VERSION "1.12"

NS_ :

BS_:

BU_: Master ODrive_Axis0

BO_ 0 Axis0_NMT: 0 Master

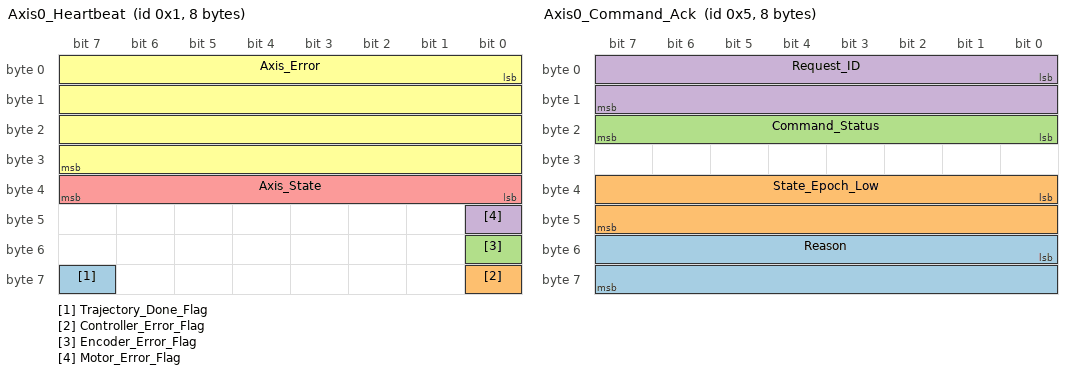
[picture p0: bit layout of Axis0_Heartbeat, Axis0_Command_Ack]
BO_ 1 Axis0_Heartbeat: 8 ODrive_Axis0
 SG_ Trajectory_Done_Flag : 63|1@1+ (1,0) [0|0] ""  Master
 SG_ Controller_Error_Flag : 56|1@1+ (1,0) [0|0] ""  Master
 SG_ Encoder_Error_Flag : 48|1@1+ (1,0) [0|0] ""  Master
 SG_ Motor_Error_Flag : 40|1@1+ (1,0) [0|0] ""  Master
 SG_ Axis_State : 32|8@1+ (1,0) [0|0] ""  Master
 SG_ Axis_Error : 0|32@1+ (1,0) [0|0] ""  Master

BO_ 2 Axis0_Estop: 0 Master

BO_ 3 Axis0_Get_Motor_Error: 8 ODrive_Axis0
 SG_ Motor_Error : 0|32@1+ (1,0) [0|0] ""  Master

BO_ 4 Axis0_Get_Encoder_Error: 8 ODrive_Axis0
 SG_ Encoder_Error : 0|32@1+ (1,0) [0|0] ""  Master

BO_ 5 Axis0_Command_Ack: 8 ODrive_Axis0
 SG_ Reason : 48|16@1+ (1,0) [0|0] ""  Master
 SG_ State_Epoch_Low : 32|16@1+ (1,0) [0|0] ""  Master
 SG_ Command_Status : 16|8@1+ (1,0) [0|0] ""  Master
 SG_ Request_ID : 0|16@1+ (1,0) [0|0] ""  Master

BO_ 6 Axis0_Set_Axis_Node_ID: 8 Master
 SG_ Axis_Node_ID : 0|32@1+ (1,0) [0|0] ""  ODrive_Axis0

BO_ 7 Axis0_Set_Axis_State: 8 Master
 SG_ Axis_Requested_State : 0|32@1+ (1,0) [0|0] ""  ODrive_Axis0

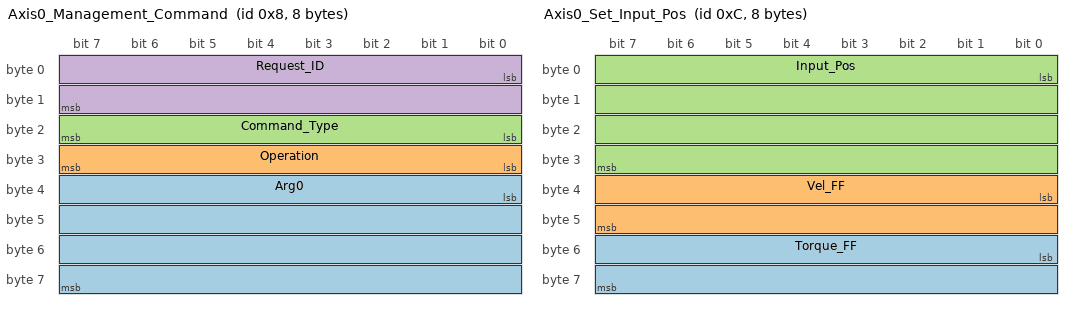
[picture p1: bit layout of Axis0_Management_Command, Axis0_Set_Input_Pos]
BO_ 8 Axis0_Management_Command: 8 Master
 SG_ Arg0 : 32|32@1+ (1,0) [0|0] ""  ODrive_Axis0
 SG_ Operation : 24|8@1+ (1,0) [0|0] ""  ODrive_Axis0
 SG_ Command_Type : 16|8@1+ (1,0) [0|0] ""  ODrive_Axis0
 SG_ Request_ID : 0|16@1+ (1,0) [0|0] ""  ODrive_Axis0

BO_ 9 Axis0_Get_Encoder_Estimates: 8 ODrive_Axis0
 SG_ Vel_Estimate : 32|32@1+ (1,0) [0|0] "rev/s"  Master
 SG_ Pos_Estimate : 0|32@1+ (1,0) [0|0] "rev"  Master

BO_ 10 Axis0_Get_Encoder_Count: 8 ODrive_Axis0
 SG_ Count_in_CPR : 32|32@1+ (1,0) [0|0] "counts"  Master
 SG_ Shadow_Count : 0|32@1+ (1,0) [0|0] "counts"  Master

BO_ 11 Axis0_Set_Controller_Mode: 8 Master
 SG_ Input_Mode : 32|32@1+ (1,0) [0|0] ""  ODrive_Axis0
 SG_ Control_Mode : 0|32@1+ (1,0) [0|0] ""  ODrive_Axis0

BO_ 12 Axis0_Set_Input_Pos: 8 Master
 SG_ Torque_FF : 48|16@1- (0.001,0) [0|0] "Nm"  ODrive_Axis0
 SG_ Vel_FF : 32|16@1- (0.001,0) [0|0] "rev/s"  ODrive_Axis0
 SG_ Input_Pos : 0|32@1+ (1,0) [0|0] "rev"  ODrive_Axis0

BO_ 13 Axis0_Set_Input_Vel: 8 Master
 SG_ Input_Torque_FF : 32|32@1+ (1,0) [0|0] "Nm"  ODrive_Axis0
 SG_ Input_Vel : 0|32@1+ (1,0) [0|0] "rev/s"  ODrive_Axis0

BO_ 14 Axis0_Set_Input_Torque: 8 Master
 SG_ Input_Torque : 0|32@1+ (1,0) [0|0] "Nm"  ODrive_Axis0

BO_ 15 Axis0_Set_Limits: 8 Master
 SG_ Current_Limit : 32|32@1+ (1,0) [0|0] "A"  ODrive_Axis0
 SG_ Velocity_Limit : 0|32@1+ (1,0) [0|0] "rev/s"  ODrive_Axis0

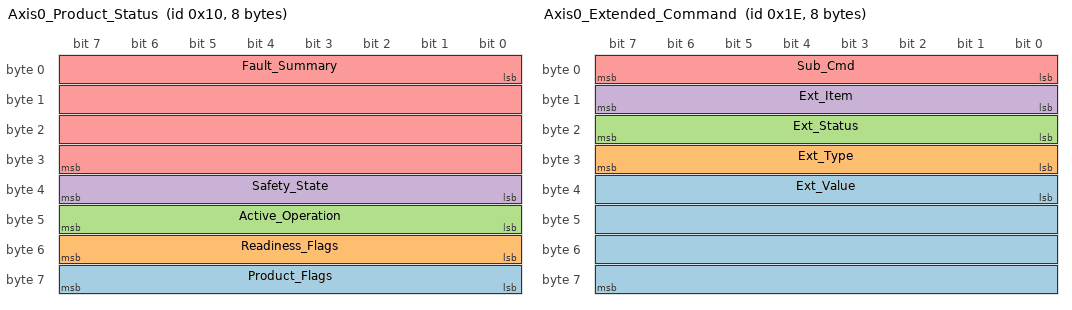
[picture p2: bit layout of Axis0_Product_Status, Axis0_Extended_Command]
BO_ 16 Axis0_Product_Status: 8 ODrive_Axis0
 SG_ Product_Flags : 56|8@1+ (1,0) [0|0] ""  Master
 SG_ Readiness_Flags : 48|8@1+ (1,0) [0|0] ""  Master
 SG_ Active_Operation : 40|8@1+ (1,0) [0|0] ""  Master
 SG_ Safety_State : 32|8@1+ (1,0) [0|0] ""  Master
 SG_ Fault_Summary : 0|32@1+ (1,0) [0|0] ""  Master

BO_ 17 Axis0_Set_Traj_Vel_Limit: 8 Master
 SG_ Traj_Vel_Limit : 0|32@1+ (1,0) [0|0] "rev/s"  ODrive_Axis0

BO_ 18 Axis0_Set_Traj_Accel_Limits: 8 Master
 SG_ Traj_Decel_Limit : 32|32@1+ (1,0) [0|0] "rev/s^2"  ODrive_Axis0
 SG_ Traj_Accel_Limit : 0|32@1+ (1,0) [0|0] "rev/s^2"  ODrive_Axis0

BO_ 19 Axis0_Set_Traj_Inertia: 8 Master
 SG_ Traj_Inertia : 0|32@1+ (1,0) [0|0] "Nm / (rev/s^2)"  ODrive_Axis0

BO_ 20 Axis0_Get_Iq: 8 ODrive_Axis0
 SG_ Iq_Measured : 32|32@1+ (1,0) [0|0] "A"  Master
 SG_ Iq_Setpoint : 0|32@1+ (1,0) [0|0] "A"  Master

BO_ 22 Axis0_Reboot: 0 Master

BO_ 23 Axis0_Get_Bus_Voltage_Current: 8 ODrive_Axis0
 SG_ Bus_Current : 32|32@1+ (1,0) [0|0] "A"  Master
 SG_ Bus_Voltage : 0|32@1+ (1,0) [0|0] "V"  Master

BO_ 24 Axis0_Clear_Errors: 0 Master

BO_ 25 Axis0_Set_Linear_Count: 8 Master
 SG_ Position : 0|32@1- (1,0) [0|0] "counts"  ODrive_Axis0

BO_ 26 Axis0_Set_Pos_Gain: 8 Master
 SG_ Pos_Gain : 0|32@1+ (1,0) [0|0] "(rev/s) / rev"  ODrive_Axis0

BO_ 27 Axis0_Set_Vel_Gains: 8 Master
 SG_ Vel_Integrator_Gain : 32|32@1+ (1,0) [0|0] "(Nm / (rev/s)) / s"  ODrive_Axis0
 SG_ Vel_Gain : 0|32@1+ (1,0) [0|0] "Nm / (rev/s)"  ODrive_Axis0

BO_ 28 Axis0_Get_ADC_Voltage: 8 ODrive_Axis0
 SG_ ADC_Voltage : 0|32@1+ (1,0) [0|0] "V"  Master

BO_ 29 Axis0_Get_Controller_Error: 8 ODrive_Axis0
 SG_ Controller_Error : 0|32@1+ (1,0) [0|0] ""  Master

BO_ 30 Axis0_Extended_Command: 8 ODrive_Axis0
 SG_ Ext_Value : 32|32@1+ (1,0) [0|0] ""  Master
 SG_ Ext_Type : 24|8@1+ (1,0) [0|0] ""  Master
 SG_ Ext_Status : 16|8@1+ (1,0) [0|0] ""  Master
 SG_ Ext_Item : 8|8@1+ (1,0) [0|0] ""  Master
 SG_ Sub_Cmd : 0|8@1+ (1,0) [0|0] ""  Master

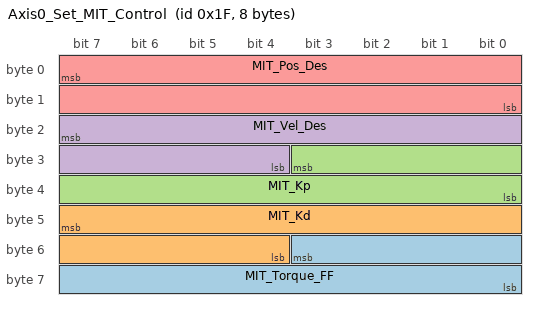
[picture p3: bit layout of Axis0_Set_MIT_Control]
BO_ 31 Axis0_Set_MIT_Control: 8 Master
 SG_ MIT_Torque_FF : 51|12@0+ (0.008791208791208791,-18.0) [-18.0|18.0] "Nm"  ODrive_Axis0
 SG_ MIT_Kd : 47|12@0+ (0.001221001221001221,0.0) [0.0|5.0] "Nm/(rad/s)"  ODrive_Axis0
 SG_ MIT_Kp : 27|12@0+ (0.1221001221001221,0.0) [0.0|500.0] "Nm/rad"  ODrive_Axis0
 SG_ MIT_Vel_Des : 23|12@0+ (0.02197802197802198,-45.0) [-45.0|45.0] "rad/s"  ODrive_Axis0
 SG_ MIT_Pos_Des : 7|16@0+ (0.00038147554741741054,-12.5) [-12.5|12.5] "rad"  ODrive_Axis0

BA_DEF_  "Baudrate" INT 0 10485760;
BA_DEF_DEF_  "Baudrate" 125000;
BA_ "Baudrate" 1000000;
VAL_ 1 Axis_State 0 "UNDEFINED" 1 "IDLE" 2 "STARTUP_SEQUENCE" 3 "FULL_CALIBRATION_SEQUENCE" 4 "MOTOR_CALIBRATION" 7 "ENCODER_OFFSET_CALIBRATION" 8 "CLOSED_LOOP_CONTROL" 9 "LOCKIN_SPIN" 11 "HOMING" ;
VAL_ 1 Axis_Error 1 "INVALID_STATE" 64 "MOTOR_FAILED" 256 "ENCODER_FAILED" 512 "CONTROLLER_FAILED" 2048 "WATCHDOG_TIMER_EXPIRED" 4096 "MIN_ENDSTOP_PRESSED" 8192 "MAX_ENDSTOP_PRESSED" 16384 "ESTOP_REQUESTED" 131072 "HOMING_WITHOUT_ENDSTOP" 262144 "OVER_TEMP" 524288 "UNKNOWN_POSITION" ;
VAL_ 3 Motor_Error 1 "PHASE_RESISTANCE_OUT_OF_RANGE" 2 "PHASE_INDUCTANCE_OUT_OF_RANGE" 8 "DRV_FAULT" 16 "CONTROL_DEADLINE_MISSED" 128 "MODULATION_MAGNITUDE" 1024 "CURRENT_SENSE_SATURATION" 4096 "CURRENT_LIMIT_VIOLATION" 65536 "MODULATION_IS_NAN" 131072 "MOTOR_THERMISTOR_OVER_TEMP" 262144 "FET_THERMISTOR_OVER_TEMP" 524288 "TIMER_UPDATE_MISSED" 1048576 "CURRENT_MEASUREMENT_UNAVAILABLE" 2097152 "CONTROLLER_FAILED" 4194304 "I_BUS_OUT_OF_RANGE" 8388608 "BRAKE_RESISTOR_DISARMED" 16777216 "SYSTEM_LEVEL" 33554432 "BAD_TIMING" 67108864 "UNKNOWN_PHASE_ESTIMATE" 134217728 "UNKNOWN_PHASE_VEL" 268435456 "UNKNOWN_TORQUE" 536870912 "UNKNOWN_CURRENT_COMMAND" 1073741824 "UNKNOWN_CURRENT_MEASUREMENT" 2147483648 "UNKNOWN_VBUS_VOLTAGE" 4294967296 "UNKNOWN_VOLTAGE_COMMAND" 8589934592 "UNKNOWN_GAINS" 17179869184 "CONTROLLER_INITIALIZING" 34359738368 "UNBALANCED_PHASES" ;
VAL_ 4 Encoder_Error 1 "UNSTABLE_GAIN" 2 "CPR_POLEPAIRS_MISMATCH" 4 "NO_RESPONSE" 8 "UNSUPPORTED_ENCODER_MODE" 64 "ABS_SPI_TIMEOUT" 128 "ABS_SPI_COM_FAIL" 256 "ABS_SPI_NOT_READY" 512 "VERNIER_RESOLVER_FAIL" ;
VAL_ 7 Axis_Requested_State 0 "UNDEFINED" 1 "IDLE" 2 "STARTUP_SEQUENCE" 3 "FULL_CALIBRATION_SEQUENCE" 4 "MOTOR_CALIBRATION" 7 "ENCODER_OFFSET_CALIBRATION" 8 "CLOSED_LOOP_CONTROL" 9 "LOCKIN_SPIN" 11 "HOMING" ;
VAL_ 11 Input_Mode 0 "INACTIVE" 1 "PASSTHROUGH" 2 "VEL_RAMP" 3 "POS_FILTER" 4 "MIX_CHANNELS" 5 "TRAP_TRAJ" 6 "TORQUE_RAMP" 8 "TUNING" 9 "MIT" ;
VAL_ 11 Control_Mode 0 "VOLTAGE_CONTROL" 1 "TORQUE_CONTROL" 2 "VELOCITY_CONTROL" 3 "POSITION_CONTROL" ;
VAL_ 29 Controller_Error 1 "OVERSPEED" 2 "INVALID_INPUT_MODE" 4 "UNSTABLE_GAIN" 8 "RESERVED_0X08" 16 "RESERVED_0X10" 32 "INVALID_ESTIMATE" 64 "INVALID_CIRCULAR_RANGE" 128 "SPINOUT_DETECTED" ;
SIG_VALTYPE_ 9 Pos_Estimate : 1;
SIG_VALTYPE_ 9 Vel_Estimate : 1;
SIG_VALTYPE_ 12 Input_Pos : 1;
SIG_VALTYPE_ 13 Input_Vel : 1;
SIG_VALTYPE_ 13 Input_Torque_FF : 1;
SIG_VALTYPE_ 14 Input_Torque : 1;
SIG_VALTYPE_ 15 Velocity_Limit : 1;
SIG_VALTYPE_ 15 Current_Limit : 1;
SIG_VALTYPE_ 17 Traj_Vel_Limit : 1;
SIG_VALTYPE_ 18 Traj_Accel_Limit : 1;
SIG_VALTYPE_ 18 Traj_Decel_Limit : 1;
SIG_VALTYPE_ 19 Traj_Inertia : 1;
SIG_VALTYPE_ 20 Iq_Setpoint : 1;
SIG_VALTYPE_ 20 Iq_Measured : 1;
SIG_VALTYPE_ 23 Bus_Voltage : 1;
SIG_VALTYPE_ 23 Bus_Current : 1;
SIG_VALTYPE_ 26 Pos_Gain : 1;
SIG_VALTYPE_ 27 Vel_Gain : 1;
SIG_VALTYPE_ 27 Vel_Integrator_Gain : 1;
SIG_VALTYPE_ 28 ADC_Voltage : 1;
